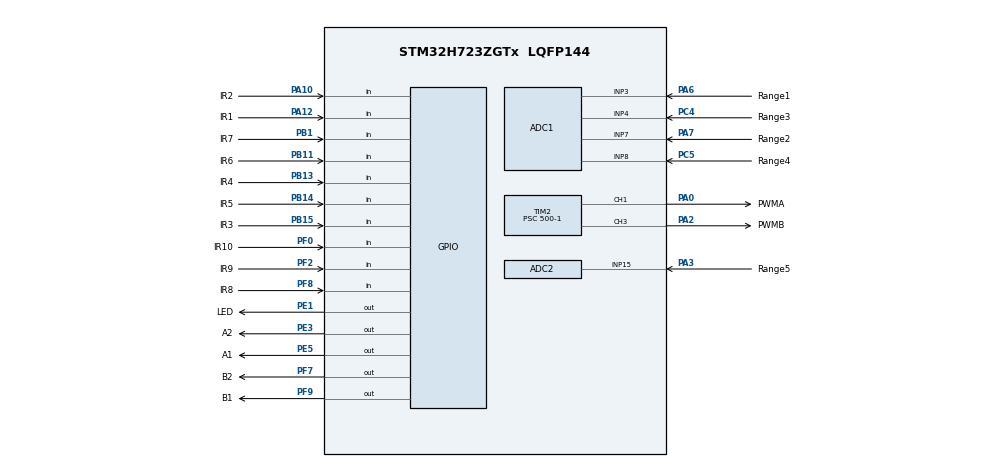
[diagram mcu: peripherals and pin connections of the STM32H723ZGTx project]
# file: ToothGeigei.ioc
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ADC1.Channel-0\#ChannelRegularConversion=ADC_CHANNEL_3
ADC1.Channel-1\#ChannelRegularConversion=ADC_CHANNEL_7
ADC1.Channel-2\#ChannelRegularConversion=ADC_CHANNEL_4
ADC1.Channel-3\#ChannelRegularConversion=ADC_CHANNEL_8
ADC1.ClockPrescaler=ADC_CLOCK_ASYNC_DIV4
ADC1.ContinuousConvMode=DISABLE
ADC1.ConversionDataManagement=ADC_CONVERSIONDATA_DMA_CIRCULAR
ADC1.DiscontinuousConvMode=DISABLE
ADC1.EOCSelection=ADC_EOC_SEQ_CONV
ADC1.ExternalTrigConv=ADC_EXTERNALTRIG_T3_TRGO
ADC1.ExternalTrigConvEdge=ADC_EXTERNALTRIGCONVEDGE_RISING
ADC1.NbrOfConversion=4
ADC1.NbrOfConversionFlag=1
ADC1.OffsetNumber-0\#ChannelRegularConversion=ADC_OFFSET_NONE
ADC1.OffsetNumber-1\#ChannelRegularConversion=ADC_OFFSET_NONE
ADC1.OffsetNumber-2\#ChannelRegularConversion=ADC_OFFSET_NONE
ADC1.OffsetNumber-3\#ChannelRegularConversion=ADC_OFFSET_NONE
ADC1.OffsetSignedSaturation-0\#ChannelRegularConversion=DISABLE
ADC1.OffsetSignedSaturation-1\#ChannelRegularConversion=DISABLE
ADC1.OffsetSignedSaturation-2\#ChannelRegularConversion=DISABLE
ADC1.OffsetSignedSaturation-3\#ChannelRegularConversion=DISABLE
ADC1.Rank-0\#ChannelRegularConversion=1
ADC1.Rank-1\#ChannelRegularConversion=2
ADC1.Rank-2\#ChannelRegularConversion=3
ADC1.Rank-3\#ChannelRegularConversion=4
ADC1.Overrun=ADC_OVR_DATA_OVERWRITTEN
ADC1.SamplingTime-0\#ChannelRegularConversion=ADC_SAMPLETIME_64CYCLES_5
ADC1.SamplingTime-1\#ChannelRegularConversion=ADC_SAMPLETIME_64CYCLES_5
ADC1.SamplingTime-2\#ChannelRegularConversion=ADC_SAMPLETIME_64CYCLES_5
ADC1.SamplingTime-3\#ChannelRegularConversion=ADC_SAMPLETIME_64CYCLES_5
ADC1.master=1
ADC2.Channel-1\#ChannelRegularConversion=ADC_CHANNEL_15
ADC2.ClockPrescaler=ADC_CLOCK_ASYNC_DIV4
ADC2.DiscontinuousConvMode=ENABLE
ADC2.NbrOfConversionFlag=1
ADC2.OffsetNumber-1\#ChannelRegularConversion=ADC_OFFSET_NONE
ADC2.OffsetSignedSaturation-1\#ChannelRegularConversion=DISABLE
ADC2.Rank-1\#ChannelRegularConversion=1
ADC2.SamplingTime-1\#ChannelRegularConversion=ADC_SAMPLETIME_1CYCLE_5
Dma.ADC1.0.Direction=DMA_PERIPH_TO_MEMORY
Dma.ADC1.0.FIFOMode=DMA_FIFOMODE_DISABLE
Dma.ADC1.0.Instance=DMA1_Stream0
Dma.ADC1.0.MemDataAlignment=DMA_MDATAALIGN_WORD
Dma.ADC1.0.MemInc=DMA_MINC_ENABLE
Dma.ADC1.0.Mode=DMA_CIRCULAR
Dma.ADC1.0.PeriphDataAlignment=DMA_PDATAALIGN_WORD
Dma.ADC1.0.PeriphInc=DMA_PINC_DISABLE
Dma.ADC1.0.Priority=DMA_PRIORITY_HIGH
Dma.ADC1.0.RequestsNb=1
Dma.Request0=ADC1
Mcu.Family=STM32H7
Mcu.Name=STM32H723ZGTx
Mcu.Package=LQFP144
NVIC.ADC_IRQn=true\:0\:1\:true\:false\:true\:true\:true
NVIC.DMA1_Stream0_IRQn=true\:0\:0\:true\:false\:true\:true\:true
NVIC.PriorityGroup=NVIC_PRIORITYGROUP_4
NVIC.TIM3_IRQn=true\:1\:0\:true\:false\:true\:true\:true
PA0.GPIO_Label=PWMA
PA0.GPIO_Speed=GPIO_SPEED_FREQ_VERY_HIGH
PA0.Signal=S_TIM2_CH1
PA10.GPIO_Label=IR2
PA10.Signal=GPIO_Input
PA12.GPIO_Label=IR1
PA12.Signal=GPIO_Input
PA13(JTMS/SWDIO).Mode=Serial_Wire
PA13(JTMS/SWDIO).Signal=DEBUG_JTMS-SWDIO
PA14(JTCK/SWCLK).Mode=Serial_Wire
PA14(JTCK/SWCLK).Signal=DEBUG_JTCK-SWCLK
PA2.GPIO_Label=PWMB
PA2.GPIO_Speed=GPIO_SPEED_FREQ_VERY_HIGH
PA2.Signal=S_TIM2_CH3
PA3.GPIO_Label=Range5
PA3.Signal=ADCx_INP15
PA6.GPIO_Label=Range1
PA6.Signal=ADCx_INP3
PA7.GPIO_Label=Range2
PA7.Signal=ADCx_INP7
PB1.GPIO_Label=IR7
PB1.Signal=GPIO_Input
PB11.GPIO_Label=IR6
PB11.Signal=GPIO_Input
PB13.GPIO_Label=IR4
PB13.Signal=GPIO_Input
PB14.GPIO_Label=IR5
PB14.Signal=GPIO_Input
PB15.GPIO_Label=IR3
PB15.Signal=GPIO_Input
PC4.GPIO_Label=Range3
PC4.Signal=ADCx_INP4
PC5.GPIO_Label=Range4
PC5.Signal=ADCx_INP8
PE1.GPIO_Label=LED
PE1.GPIO_PuPd=GPIO_PULLUP
PE1.GPIO_Speed=GPIO_SPEED_FREQ_VERY_HIGH
PE1.PinState=GPIO_PIN_RESET
PE1.Signal=GPIO_Output
PE3.GPIO_Label=A2
PE3.GPIO_PuPd=GPIO_PULLUP
PE3.GPIO_Speed=GPIO_SPEED_FREQ_VERY_HIGH
PE3.Signal=GPIO_Output
PE5.GPIO_Label=A1
PE5.GPIO_PuPd=GPIO_PULLUP
PE5.GPIO_Speed=GPIO_SPEED_FREQ_VERY_HIGH
PE5.Signal=GPIO_Output
PF0.GPIO_Label=IR10
PF0.Signal=GPIO_Input
PF2.GPIO_Label=IR9
PF2.Signal=GPIO_Input
PF7.GPIO_Label=B2
PF7.GPIO_Speed=GPIO_SPEED_FREQ_VERY_HIGH
PF7.Signal=GPIO_Output
PF8.GPIO_Label=IR8
PF8.Signal=GPIO_Input
PF9.GPIO_Label=B1
PF9.GPIO_Speed=GPIO_SPEED_FREQ_VERY_HIGH
PF9.Signal=GPIO_Output
ProjectManager.HeapSize=0x200
ProjectManager.StackSize=0x400
ProjectManager.TargetToolchain=MDK-ARM V5.27
RCC.ADCFreq_Value=96000000
RCC.APB1Freq_Value=125000000
RCC.APB2Freq_Value=125000000
RCC.APB3Freq_Value=125000000
RCC.APB4Freq_Value=125000000
RCC.CortexFreq_Value=500000000
RCC.D1PPRE=RCC_APB3_DIV2
RCC.D2PPRE1=RCC_APB1_DIV2
RCC.D2PPRE2=RCC_APB2_DIV2
RCC.D3PPRE=RCC_APB4_DIV2
RCC.DIVM1=4
RCC.DIVM2=4
RCC.DIVN1=31
RCC.DIVN2=12
RCC.DIVP1=1
RCC.HCLKFreq_Value=250000000
RCC.HPRE=RCC_HCLK_DIV2
RCC.PLL2FRACN=0
RCC.PLL3FRACN=0
RCC.PLLFRACN=2048
RCC.SYSCLKFreq_VALUE=500000000
RCC.SYSCLKSource=RCC_SYSCLKSOURCE_PLLCLK
RCC.USBFreq_Value=250000000
SH.ADCx_INP15.0=ADC2_INP15,IN15-Single-Ended
SH.ADCx_INP3.0=ADC1_INP3,IN3-Single-Ended
SH.ADCx_INP4.0=ADC1_INP4,IN4-Single-Ended
SH.ADCx_INP7.0=ADC1_INP7,IN7-Single-Ended
SH.ADCx_INP8.0=ADC1_INP8,IN8-Single-Ended
SH.S_TIM2_CH1.0=TIM2_CH1,PWM Generation1 CH1
SH.S_TIM2_CH3.0=TIM2_CH3,PWM Generation3 CH3
TIM2.Channel-PWM\ Generation1\ CH1=TIM_CHANNEL_1
TIM2.Channel-PWM\ Generation3\ CH3=TIM_CHANNEL_3
TIM2.Period=100-1
TIM2.Prescaler=500-1
TIM3.AutoReloadPreload=TIM_AUTORELOAD_PRELOAD_ENABLE
TIM3.MasterOutputTrigger=TIM_TRGO_UPDATE
TIM3.Period=1000-1
TIM3.Prescaler=250-1
VP_TIM2_VS_ClockSourceINT.Mode=Internal
VP_TIM3_VS_ClockSourceINT.Mode=Internal
board=custom

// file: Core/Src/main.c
/* USER CODE BEGIN Header */
/**
  ******************************************************************************
  * @file           : main.c
  * @brief          : Main program body
  ******************************************************************************
  * @attention
  *
  * <h2><center>&copy; Copyright (c) 2024 STMicroelectronics.
  * All rights reserved.</center></h2>
  *
  * This software component is licensed by ST under BSD 3-Clause license,
  * the "License"; You may not use this file except in compliance with the
  * License. You may obtain a copy of the License at:
  *                        opensource.org/licenses/BSD-3-Clause
  *
  ******************************************************************************
  */
/* USER CODE END Header */
#include "main.h"
#include "dma.h"
#include "adc.h"
#include "tim.h"
#include "gpio.h"

/* USER CODE BEGIN Includes */
#include "User.h"

/* USER CODE END Includes */

void SystemClock_Config(void);
void PeriphCommonClock_Config(void);

int main(void)
{

  /* MCU Configuration--------------------------------------------------------*/

  /* Reset of all peripherals, Initializes the Flash interface and the Systick. */
  HAL_Init();

  /* Configure the system clock */
  SystemClock_Config();

/* Configure the peripherals common clocks */
  PeriphCommonClock_Config();

  /* Initialize all configured peripherals */
  MX_GPIO_Init();
  MX_DMA_Init();
  MX_ADC1_Init();
  MX_TIM2_Init();
  MX_TIM3_Init();
  MX_ADC2_Init();
  /* USER CODE BEGIN 2 */

	User_Init();
  /* USER CODE END 2 */

  /* Infinite loop */
  while (1)
  {

    /* USER CODE BEGIN 3 */
	  while(1)User_While();
  }
  /* USER CODE END 3 */
}

void SystemClock_Config(void)
{
  RCC_OscInitTypeDef RCC_OscInitStruct = {0};
  RCC_ClkInitTypeDef RCC_ClkInitStruct = {0};

  /** Supply configuration update enable
  */
  HAL_PWREx_ConfigSupply(PWR_LDO_SUPPLY);
  /** Configure the main internal regulator output voltage
  */
  __HAL_PWR_VOLTAGESCALING_CONFIG(PWR_REGULATOR_VOLTAGE_SCALE0);

  while(!__HAL_PWR_GET_FLAG(PWR_FLAG_VOSRDY)) {}
  /** Macro to configure the PLL clock source
  */
  __HAL_RCC_PLL_PLLSOURCE_CONFIG(RCC_PLLSOURCE_HSI);
  /** Initializes the RCC Oscillators according to the specified parameters
  * in the RCC_OscInitTypeDef structure.
  */
  RCC_OscInitStruct.OscillatorType = RCC_OSCILLATORTYPE_HSI;
  RCC_OscInitStruct.HSIState = RCC_HSI_DIV1;
  RCC_OscInitStruct.HSICalibrationValue = RCC_HSICALIBRATION_DEFAULT;
  RCC_OscInitStruct.PLL.PLLState = RCC_PLL_ON;
  RCC_OscInitStruct.PLL.PLLSource = RCC_PLLSOURCE_HSI;
  RCC_OscInitStruct.PLL.PLLM = 4;
  RCC_OscInitStruct.PLL.PLLN = 31;
  RCC_OscInitStruct.PLL.PLLP = 1;
  RCC_OscInitStruct.PLL.PLLQ = 2;
  RCC_OscInitStruct.PLL.PLLR = 2;
  RCC_OscInitStruct.PLL.PLLRGE = RCC_PLL1VCIRANGE_3;
  RCC_OscInitStruct.PLL.PLLVCOSEL = RCC_PLL1VCOWIDE;
  RCC_OscInitStruct.PLL.PLLFRACN = 2048;
  if (HAL_RCC_OscConfig(&RCC_OscInitStruct) != HAL_OK)
  {
    Error_Handler();
  }
  /** Initializes the CPU, AHB and APB buses clocks
  */
  RCC_ClkInitStruct.ClockType = RCC_CLOCKTYPE_HCLK|RCC_CLOCKTYPE_SYSCLK
                              |RCC_CLOCKTYPE_PCLK1|RCC_CLOCKTYPE_PCLK2
                              |RCC_CLOCKTYPE_D3PCLK1|RCC_CLOCKTYPE_D1PCLK1;
  RCC_ClkInitStruct.SYSCLKSource = RCC_SYSCLKSOURCE_PLLCLK;
  RCC_ClkInitStruct.SYSCLKDivider = RCC_SYSCLK_DIV1;
  RCC_ClkInitStruct.AHBCLKDivider = RCC_HCLK_DIV2;
  RCC_ClkInitStruct.APB3CLKDivider = RCC_APB3_DIV2;
  RCC_ClkInitStruct.APB1CLKDivider = RCC_APB1_DIV2;
  RCC_ClkInitStruct.APB2CLKDivider = RCC_APB2_DIV2;
  RCC_ClkInitStruct.APB4CLKDivider = RCC_APB4_DIV2;

  if (HAL_RCC_ClockConfig(&RCC_ClkInitStruct, FLASH_LATENCY_3) != HAL_OK)
  {
    Error_Handler();
  }
}

void PeriphCommonClock_Config(void)
{
  RCC_PeriphCLKInitTypeDef PeriphClkInitStruct = {0};

  /** Initializes the peripherals clock
  */
  PeriphClkInitStruct.PeriphClockSelection = RCC_PERIPHCLK_ADC;
  PeriphClkInitStruct.PLL2.PLL2M = 4;
  PeriphClkInitStruct.PLL2.PLL2N = 12;
  PeriphClkInitStruct.PLL2.PLL2P = 2;
  PeriphClkInitStruct.PLL2.PLL2Q = 2;
  PeriphClkInitStruct.PLL2.PLL2R = 2;
  PeriphClkInitStruct.PLL2.PLL2RGE = RCC_PLL2VCIRANGE_3;
  PeriphClkInitStruct.PLL2.PLL2VCOSEL = RCC_PLL2VCOWIDE;
  PeriphClkInitStruct.PLL2.PLL2FRACN = 0;
  PeriphClkInitStruct.AdcClockSelection = RCC_ADCCLKSOURCE_PLL2;
  if (HAL_RCCEx_PeriphCLKConfig(&PeriphClkInitStruct) != HAL_OK)
  {
    Error_Handler();
  }
}

void Error_Handler(void)
{
  __disable_irq();
  while (1)
  {
  }
}

/************************ (C) COPYRIGHT STMicroelectronics *****END OF FILE****/
